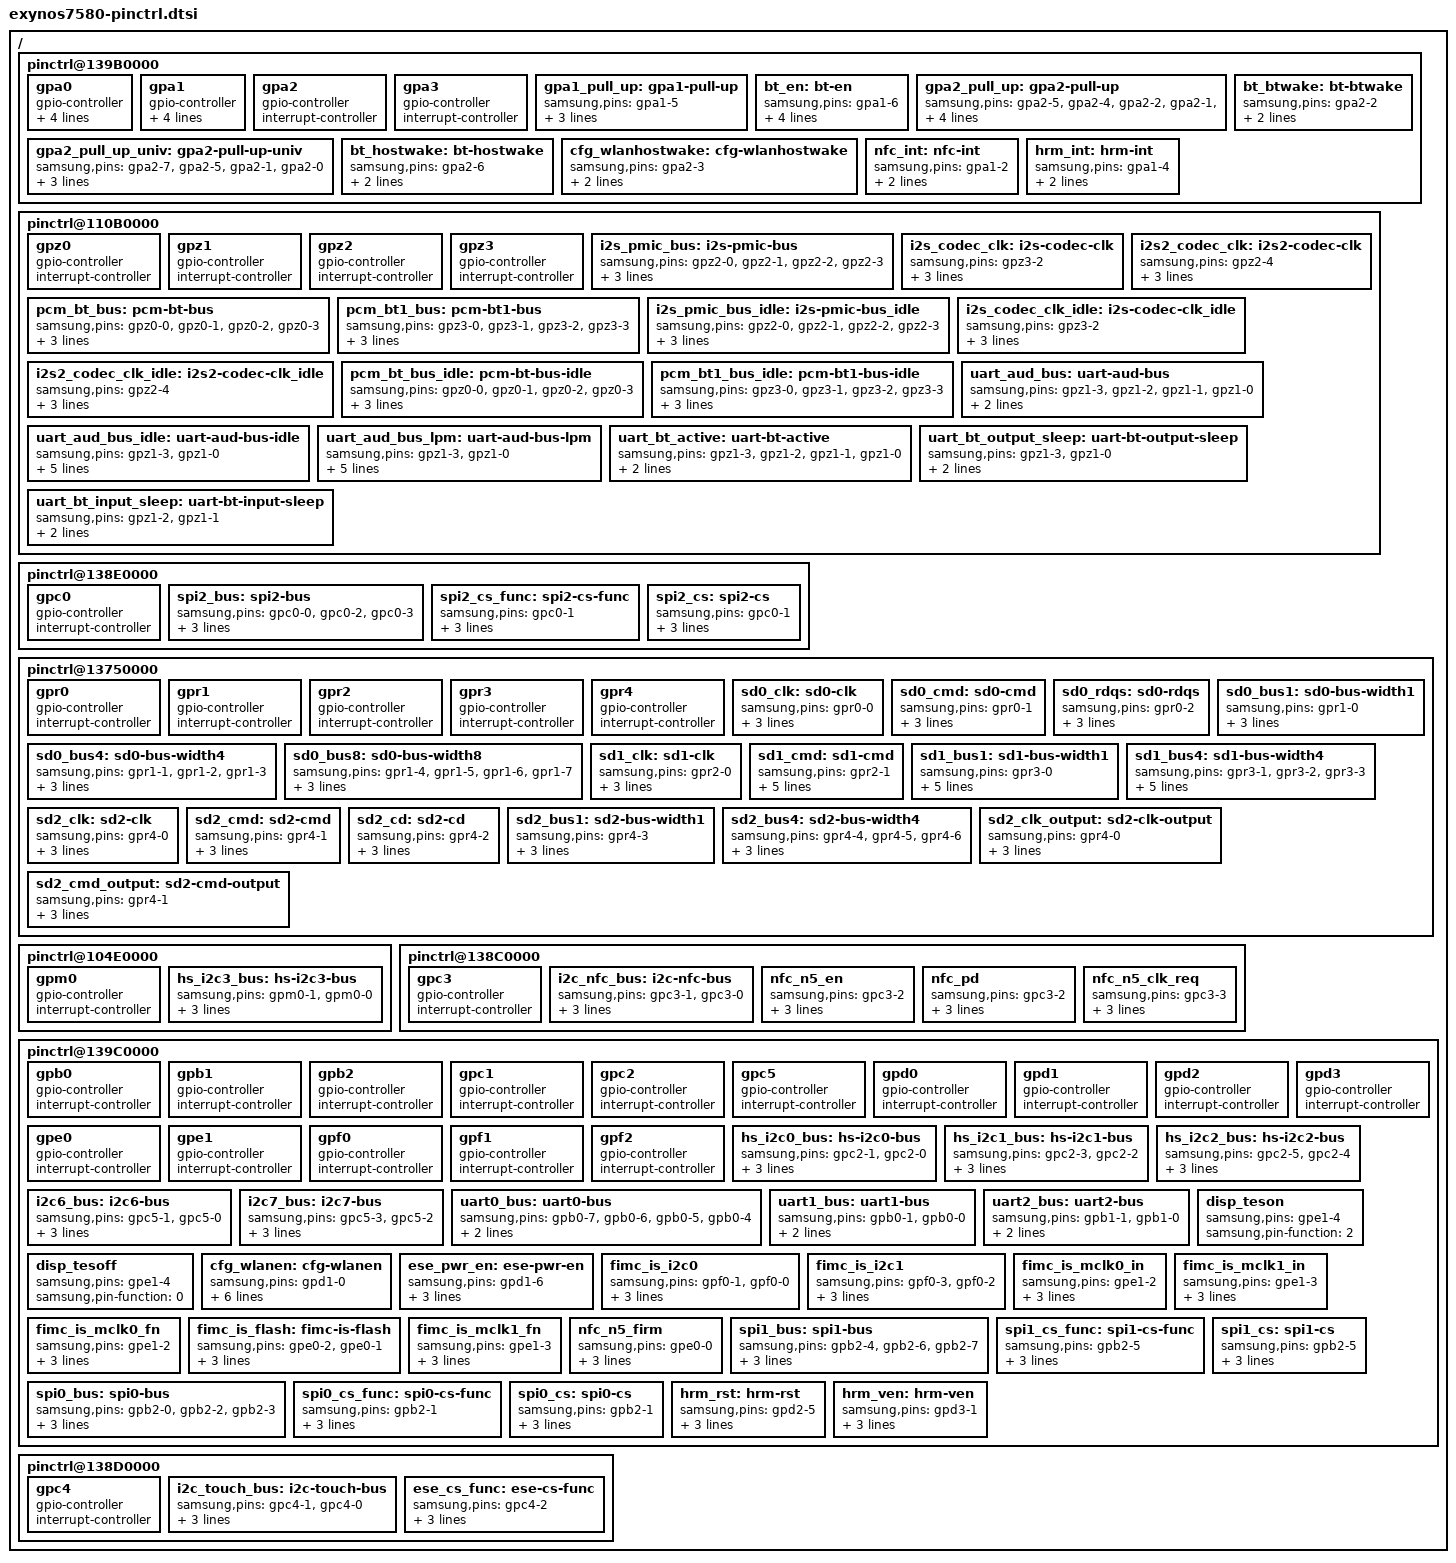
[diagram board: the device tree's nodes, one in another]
/*
 * Samsung's Exynos7580 SoC pin-mux and pin-config device tree source
 *
 * Copyright (c) 2014 Samsung Electronics Co., Ltd.
 *		http://www.samsung.com
 *
 * Samsung's Exynos7580 SoC pin-mux and pin-config options are listed as device
 * tree nodes are listed in this file.
 *
 * This program is free software; you can redistribute it and/or modify
 * it under the terms of the GNU General Public License version 2 as
 * published by the Free Software Foundation.
*/

/ {
	pinctrl@139B0000 {
		gpa0: gpa0 {
			gpio-controller;
			#gpio-cells = <2>;

			interrupt-controller;
			#interrupt-cells = <3>;
			interrupt-parent = <&gic>;
			interrupts = <0 0 0>, <0 1 0>, <0 2 0>, <0 3 0>,
				     <0 4 0>, <0 5 0>, <0 6 0>, <0 7 0>;
		};

		gpa1: gpa1 {
			gpio-controller;
			#gpio-cells = <2>;

			interrupt-controller;
			#interrupt-cells = <3>;
			interrupt-parent = <&gic>;
			interrupts = <0 8 0>, <0 9 0>, <0 10 0>, <0 11 0>,
				     <0 12 0>, <0 13 0>, <0 14 0>, <0 15 0>;
		};

		gpa2: gpa2 {
			gpio-controller;
			#gpio-cells = <2>;

			interrupt-controller;
			#interrupt-cells = <2>;
		};

		gpa3: gpa3 {
			gpio-controller;
			#gpio-cells = <2>;

			interrupt-controller;
			#interrupt-cells = <2>;
		};

		gpa1_pull_up: gpa1-pull-up {
			samsung,pins = "gpa1-5";
			samsung,pin-function = <0xf>;
			samsung,pin-pud = <3>;
			samsung,pin-drv = <0>;
		};

		bt_en: bt-en {
			samsung,pins ="gpa1-6";
			samsung,pin-function = <1>;
			samsung,pin-pud = <0>;
			samsung,pin-con-pdn = <3>;
			samsung,pin-pud-pdn = <0>;
		};

		gpa2_pull_up: gpa2-pull-up {
			samsung,pins = "gpa2-5", "gpa2-4", "gpa2-2", "gpa2-1", "gpa2-0";
			samsung,pin-function = <0xf>;
			samsung,pin-pud = <3>;
			samsung,pin-drv = <0>;
		};

		gpa2_pull_up_univ: gpa2-pull-up-univ {
			samsung,pins = "gpa2-7", "gpa2-5", "gpa2-1", "gpa2-0";
			samsung,pin-function = <0xf>;
			samsung,pin-pud = <3>;
			samsung,pin-drv = <0>;
		};

		bt_btwake: bt-btwake {
			samsung,pins = "gpa2-2";
			samsung,pin-function = <1>;
			samsung,pin-pud = <0>;
		};

		bt_hostwake: bt-hostwake {
			samsung,pins = "gpa2-6";
			samsung,pin-function = <0>;
			samsung,pin-pud = <0>;
		};
		
		cfg_wlanhostwake: cfg-wlanhostwake {
                	samsung,pins = "gpa2-3";
                	samsung,pin-function = <0>;
                	samsung,pin-pud = <1>;
                };

		nfc_int: nfc-int {
			samsung,pins = "gpa1-2";
			samsung,pin-function = <0>;
			samsung,pin-pud = <1>;
		};

		hrm_int: hrm-int {
			samsung,pins = "gpa1-4";
			samsung,pin-function = <0xf>;
			samsung,pin-pud = <1>;
		};
	};

	pinctrl@110B0000 {
		gpz0: gpz0 {
			gpio-controller;
			#gpio-cells = <2>;

			interrupt-controller;
			#interrupt-cells = <2>;
		};

		gpz1: gpz1 {
			gpio-controller;
			#gpio-cells = <2>;

			interrupt-controller;
			#interrupt-cells = <2>;
		};

		gpz2: gpz2 {
			gpio-controller;
			#gpio-cells = <2>;

			interrupt-controller;
			#interrupt-cells = <2>;
		};

		gpz3: gpz3 {
			gpio-controller;
			#gpio-cells = <2>;

			interrupt-controller;
			#interrupt-cells = <2>;
		};

		i2s_pmic_bus: i2s-pmic-bus {
			samsung,pins = "gpz2-0", "gpz2-1", "gpz2-2", "gpz2-3";
			samsung,pin-function = <2>;
			samsung,pin-pud = <1>;
			samsung,pin-drv = <0>;
		};

		i2s_codec_clk: i2s-codec-clk {
			samsung,pins = "gpz3-2";
			samsung,pin-function = <4>;
			samsung,pin-pud = <1>;
			samsung,pin-drv = <0>;
		};

		/* XTSCPU_TOUT pin configuration as codec MCLK */
		i2s2_codec_clk: i2s2-codec-clk {
			samsung,pins = "gpz2-4";
			samsung,pin-function = <2>;
			samsung,pin-pud = <1>;
			samsung,pin-drv = <0>;
		};

		pcm_bt_bus: pcm-bt-bus {
			samsung,pins = "gpz0-0", "gpz0-1", "gpz0-2", "gpz0-3";
			samsung,pin-function = <2>;
			samsung,pin-pud = <1>;
			samsung,pin-drv = <0>;
		};

		pcm_bt1_bus: pcm-bt1-bus {
			samsung,pins = "gpz3-0", "gpz3-1", "gpz3-2", "gpz3-3";
			samsung,pin-function = <2>;
			samsung,pin-pud = <1>;
			samsung,pin-drv = <0>;
		};

		i2s_pmic_bus_idle: i2s-pmic-bus_idle {
			samsung,pins = "gpz2-0", "gpz2-1", "gpz2-2", "gpz2-3";
			samsung,pin-function = <0>;
			samsung,pin-pud = <1>;
			samsung,pin-drv = <0>;
		};

		i2s_codec_clk_idle: i2s-codec-clk_idle {
			samsung,pins = "gpz3-2";
			samsung,pin-function = <0>;
			samsung,pin-pud = <1>;
			samsung,pin-drv = <0>;
		};

		i2s2_codec_clk_idle: i2s2-codec-clk_idle {
			samsung,pins = "gpz2-4";
			samsung,pin-function = <0>;
			samsung,pin-pud = <1>;
			samsung,pin-drv = <0>;
		};

		pcm_bt_bus_idle: pcm-bt-bus-idle {
			samsung,pins = "gpz0-0", "gpz0-1", "gpz0-2", "gpz0-3";
			samsung,pin-function = <0>;
			samsung,pin-pud = <1>;
			samsung,pin-drv = <0>;
		};

		pcm_bt1_bus_idle: pcm-bt1-bus-idle {
			samsung,pins = "gpz3-0", "gpz3-1", "gpz3-2", "gpz3-3";
			samsung,pin-function = <0>;
			samsung,pin-pud = <1>;
			samsung,pin-drv = <0>;
		};

		uart_aud_bus: uart-aud-bus {
			samsung,pins = "gpz1-3", "gpz1-2", "gpz1-1", "gpz1-0";
			samsung,pin-function = <2>;
			samsung,pin-pud = <0>;
		};

		uart_aud_bus_idle: uart-aud-bus-idle {
			samsung,pins = "gpz1-3", "gpz1-0";
			samsung,pin-function = <1>;
			samsung,pin-val = <1>;
			samsung,pin-pud = <0>;
			samsung,pin-con-pdn = <1>;
			samsung,pin-pud-pdn = <3>;
		};

		uart_aud_bus_lpm: uart-aud-bus-lpm {
			samsung,pins = "gpz1-3", "gpz1-0";
			samsung,pin-function = <1>;
			samsung,pin-val = <1>;
			samsung,pin-pud = <0>;
			samsung,pin-con-pdn = <1>;
			samsung,pin-pud-pdn = <3>;
		};

		uart_bt_active: uart-bt-active {
			samsung,pins = "gpz1-3", "gpz1-2", "gpz1-1", "gpz1-0";
			samsung,pin-function = <2>;
			samsung,pin-pud = <3>;
		};

		uart_bt_output_sleep: uart-bt-output-sleep {
			samsung,pins = "gpz1-3", "gpz1-0";
			samsung,pin-con-pdn = <1>;
			samsung,pin-pud-pdn = <3>;
		};

		uart_bt_input_sleep: uart-bt-input-sleep {
			samsung,pins = "gpz1-2", "gpz1-1";
			samsung,pin-con-pdn = <2>;
			samsung,pin-pud-pdn = <3>;
		};
	};

	pinctrl@138E0000 {
		gpc0: gpc0 {
			gpio-controller;
			#gpio-cells = <2>;

			interrupt-controller;
			#interrupt-cells = <2>;
		};

		spi2_bus: spi2-bus {
			samsung,pins = "gpc0-0", "gpc0-2", "gpc0-3";
			samsung,pin-function = <2>;
			samsung,pin-pud = <3>;
			samsung,pin-drv = <0>;
		};

		spi2_cs_func: spi2-cs-func {
			samsung,pins = "gpc0-1";
			samsung,pin-function = <2>;
			samsung,pin-pud = <3>;
			samsung,pin-drv = <0>;
		};

		spi2_cs: spi2-cs {
			samsung,pins = "gpc0-1";
			samsung,pin-function = <1>;
			samsung,pin-pud = <3>;
			samsung,pin-drv = <0>;
		};
	};

	pinctrl@13750000 {
		gpr0: gpr0 {
			gpio-controller;
			#gpio-cells = <2>;

			interrupt-controller;
			#interrupt-cells = <2>;
		};

		gpr1: gpr1 {
			gpio-controller;
			#gpio-cells = <2>;

			interrupt-controller;
			#interrupt-cells = <2>;
		};

		gpr2: gpr2 {
			gpio-controller;
			#gpio-cells = <2>;

			interrupt-controller;
			#interrupt-cells = <2>;
		};

		gpr3: gpr3 {
			gpio-controller;
			#gpio-cells = <2>;

			interrupt-controller;
			#interrupt-cells = <2>;
		};

		gpr4: gpr4 {
			gpio-controller;
			#gpio-cells = <2>;

			interrupt-controller;
			#interrupt-cells = <2>;
		};

		sd0_clk: sd0-clk {
			samsung,pins = "gpr0-0";
			samsung,pin-function = <2>;
			samsung,pin-pud = <0>;
			samsung,pin-drv = <2>;
		};

		sd0_cmd: sd0-cmd {
			samsung,pins = "gpr0-1";
			samsung,pin-function = <2>;
			samsung,pin-pud = <3>;
			samsung,pin-drv = <2>;
		};

		sd0_rdqs: sd0-rdqs {
			samsung,pins = "gpr0-2";
			samsung,pin-function = <2>;
			samsung,pin-pud = <1>;
			samsung,pin-drv = <2>;
		};

		sd0_bus1: sd0-bus-width1 {
			samsung,pins = "gpr1-0";
			samsung,pin-function = <2>;
			samsung,pin-pud = <3>;
			samsung,pin-drv = <2>;
		};

		sd0_bus4: sd0-bus-width4 {
			samsung,pins = "gpr1-1", "gpr1-2", "gpr1-3";
			samsung,pin-function = <2>;
			samsung,pin-pud = <3>;
			samsung,pin-drv = <2>;
		};

		sd0_bus8: sd0-bus-width8 {
			samsung,pins = "gpr1-4", "gpr1-5", "gpr1-6", "gpr1-7";
			samsung,pin-function = <2>;
			samsung,pin-pud = <3>;
			samsung,pin-drv = <2>;
		};

		sd1_clk: sd1-clk {
			samsung,pins = "gpr2-0";
			samsung,pin-function = <2>;
			samsung,pin-pud = <0>;
			samsung,pin-drv = <3>;
		};

		sd1_cmd: sd1-cmd {
			samsung,pins = "gpr2-1";
			samsung,pin-function = <2>;
			samsung,pin-pud = <3>;
			samsung,pin-drv = <3>;
			samsung,pin-con-pdn = <2>;
			samsung,pin-pud-pdn = <3>;
		};

		sd1_bus1: sd1-bus-width1 {
			samsung,pins = "gpr3-0";
			samsung,pin-function = <2>;
			samsung,pin-pud = <3>;
			samsung,pin-drv = <3>;
			samsung,pin-con-pdn = <2>;
			samsung,pin-pud-pdn = <3>;
		};

		sd1_bus4: sd1-bus-width4 {
			samsung,pins = "gpr3-1", "gpr3-2", "gpr3-3";
			samsung,pin-function = <2>;
			samsung,pin-pud = <3>;
			samsung,pin-drv = <3>;
			samsung,pin-con-pdn = <2>;
			samsung,pin-pud-pdn = <3>;
		};

		sd2_clk: sd2-clk {
			samsung,pins = "gpr4-0";
			samsung,pin-function = <2>;
			samsung,pin-pud = <0>;
			samsung,pin-drv = <2>;
		};

		sd2_cmd: sd2-cmd {
			samsung,pins = "gpr4-1";
			samsung,pin-function = <2>;
			samsung,pin-pud = <0>;
			samsung,pin-drv = <2>;
		};

		sd2_cd: sd2-cd {
			samsung,pins = "gpr4-2";
			samsung,pin-function = <2>;
			samsung,pin-pud = <0>;
			samsung,pin-drv = <2>;
		};

		sd2_bus1: sd2-bus-width1 {
			samsung,pins = "gpr4-3";
			samsung,pin-function = <2>;
			samsung,pin-pud = <0>;
			samsung,pin-drv = <2>;
		};

		sd2_bus4: sd2-bus-width4 {
			samsung,pins = "gpr4-4", "gpr4-5", "gpr4-6";
			samsung,pin-function = <2>;
			samsung,pin-pud = <0>;
			samsung,pin-drv = <2>;
		};

		sd2_clk_output: sd2-clk-output {
			samsung,pins = "gpr4-0";
			samsung,pin-function = <1>;
			samsung,pin-pud = <0>;
			samsung,pin-drv = <2>;
		};

		sd2_cmd_output: sd2-cmd-output {
			samsung,pins = "gpr4-1";
			samsung,pin-function = <1>;
			samsung,pin-pud = <0>;
			samsung,pin-drv = <2>;
		};

	};

	pinctrl@104E0000 {
		gpm0: gpm0 {
			gpio-controller;
			#gpio-cells = <2>;

			interrupt-controller;
			#interrupt-cells = <2>;
		};

		hs_i2c3_bus: hs-i2c3-bus {
			samsung,pins = "gpm0-1", "gpm0-0";
			samsung,pin-function = <2>;
			samsung,pin-pud = <3>;
			samsung,pin-drv = <2>;
		};
	};

	pinctrl@138C0000 {
		gpc3: gpc3 {
			gpio-controller;
			#gpio-cells = <2>;

			interrupt-controller;
			#interrupt-cells = <2>;
		};

		i2c_nfc_bus: i2c-nfc-bus {
			samsung,pins = "gpc3-1", "gpc3-0";
			samsung,pin-function = <2>;
			samsung,pin-pud = <3>;
			samsung,pin-drv = <0>;
		};

		nfc_n5_en: nfc_n5_en {
			samsung,pins = "gpc3-2";
			samsung,pin-function = <1>;
			samsung,pin-pud = <1>;
			samsung,pin-val = <1>;
		};

		nfc_pd: nfc_pd {
			samsung,pins = "gpc3-2";
			samsung,pin-function = <2>;
			samsung,pin-pud = <1>;
			samsung,pin-drv = <0>;
		};

		nfc_n5_clk_req: nfc_n5_clk_req {
			samsung,pins = "gpc3-3";
			samsung,pin-function = <2>;
			samsung,pin-pud = <1>;
			samsung,pin-drv = <0>;
		};
	};

	pinctrl@139C0000 {
		gpb0: gpb0 {
			gpio-controller;
			#gpio-cells = <2>;

			interrupt-controller;
			#interrupt-cells = <2>;
		};

		gpb1: gpb1 {
			gpio-controller;
			#gpio-cells = <2>;

			interrupt-controller;
			#interrupt-cells = <2>;
		};

		gpb2: gpb2 {
			gpio-controller;
			#gpio-cells = <2>;

			interrupt-controller;
			#interrupt-cells = <2>;
		};

		gpc1: gpc1 {
			gpio-controller;
			#gpio-cells = <2>;

			interrupt-controller;
			#interrupt-cells = <2>;
		};

		gpc2: gpc2 {
			gpio-controller;
			#gpio-cells = <2>;

			interrupt-controller;
			#interrupt-cells = <2>;
		};

		gpc5: gpc5 {
			gpio-controller;
			#gpio-cells = <2>;

			interrupt-controller;
			#interrupt-cells = <2>;
		};

		gpd0: gpd0 {
			gpio-controller;
			#gpio-cells = <2>;

			interrupt-controller;
			#interrupt-cells = <2>;
		};

		gpd1: gpd1 {
			gpio-controller;
			#gpio-cells = <2>;

			interrupt-controller;
			#interrupt-cells = <2>;
		};

		gpd2: gpd2 {
			gpio-controller;
			#gpio-cells = <2>;

			interrupt-controller;
			#interrupt-cells = <2>;
		};

		gpd3: gpd3 {
			gpio-controller;
			#gpio-cells = <2>;

			interrupt-controller;
			#interrupt-cells = <2>;
		};

		gpe0: gpe0 {
			gpio-controller;
			#gpio-cells = <2>;

			interrupt-controller;
			#interrupt-cells = <2>;
		};

		gpe1: gpe1 {
			gpio-controller;
			#gpio-cells = <2>;

			interrupt-controller;
			#interrupt-cells = <2>;
		};

		gpf0: gpf0 {
			gpio-controller;
			#gpio-cells = <2>;

			interrupt-controller;
			#interrupt-cells = <2>;
		};

		gpf1: gpf1 {
			gpio-controller;
			#gpio-cells = <2>;

			interrupt-controller;
			#interrupt-cells = <2>;
		};

		gpf2: gpf2 {
			gpio-controller;
			#gpio-cells = <2>;

			interrupt-controller;
			#interrupt-cells = <2>;
		};

		hs_i2c0_bus: hs-i2c0-bus {
			samsung,pins = "gpc2-1", "gpc2-0";
			samsung,pin-function = <2>;
			samsung,pin-pud = <3>;
			samsung,pin-drv = <0>;
		};

		hs_i2c1_bus: hs-i2c1-bus {
			samsung,pins = "gpc2-3", "gpc2-2";
			samsung,pin-function = <2>;
			samsung,pin-pud = <3>;
			samsung,pin-drv = <0>;
		};

		hs_i2c2_bus: hs-i2c2-bus {
			samsung,pins = "gpc2-5", "gpc2-4";
			samsung,pin-function = <2>;
			samsung,pin-pud = <0>;
			samsung,pin-drv = <0>;
		};

		i2c6_bus: i2c6-bus {
			samsung,pins = "gpc5-1", "gpc5-0";
			samsung,pin-function = <2>;
			samsung,pin-pud = <3>;
			samsung,pin-drv = <0>;
		};

		i2c7_bus: i2c7-bus {
			samsung,pins = "gpc5-3", "gpc5-2";
			samsung,pin-function = <2>;
			samsung,pin-pud = <3>;
			samsung,pin-drv = <0>;
		};

		uart0_bus: uart0-bus {
			samsung,pins = "gpb0-7", "gpb0-6", "gpb0-5", "gpb0-4";
			samsung,pin-function = <2>;
			samsung,pin-pud = <0>;
		};

		uart1_bus: uart1-bus {
			samsung,pins = "gpb0-1", "gpb0-0";
			samsung,pin-function = <2>;
			samsung,pin-pud = <0>;
		};

		uart2_bus: uart2-bus {
			samsung,pins = "gpb1-1", "gpb1-0";
			samsung,pin-function = <2>;
			samsung,pin-pud = <0>;
		};

		disp_teson: disp_teson {
			samsung,pins = "gpe1-4";
			samsung,pin-function = <2>;
		};

		disp_tesoff: disp_tesoff {
			samsung,pins = "gpe1-4";
			samsung,pin-function = <0>;
		};
		
		cfg_wlanen: cfg-wlanen  {       /* WLAN_EN on carmen2 */
                	samsung,pins = "gpd1-0";
                	samsung,pin-function = <1>;
                	samsung,pin-pud = <0>;
                	samsung,pin-drv = <3>;
                	samsung,pin-con-pdn = <3>;
                	samsung,pin-pud-pdn = <0>;
			samsung,pin-val = <0>;
                };

		ese_pwr_en: ese-pwr-en {
			samsung,pins = "gpd1-6";
			samsung,pin-function = <1>;
			samsung,pin-pud = <1>;
			samsung,pin-drv = <3>;
		};

		fimc_is_i2c0: fimc_is_i2c0 {
			samsung,pins = "gpf0-1", "gpf0-0";
			samsung,pin-function = <2>;
			samsung,pin-pud = <0>;
			samsung,pin-drv = <0>;
		};

		fimc_is_i2c1: fimc_is_i2c1 {
			samsung,pins = "gpf0-3", "gpf0-2";
			samsung,pin-function = <2>;
			samsung,pin-pud = <0>;
			samsung,pin-drv = <0>;
		};

		fimc_is_mclk0_in: fimc_is_mclk0_in {
			samsung,pins = "gpe1-2";
			samsung,pin-function = <0>;
			samsung,pin-pud = <0>;
			samsung,pin-drv = <0>;
		};

		fimc_is_mclk1_in: fimc_is_mclk1_in {
			samsung,pins = "gpe1-3";
			samsung,pin-function = <0>;
			samsung,pin-pud = <0>;
			samsung,pin-drv = <0>;
		};

		fimc_is_mclk0_fn: fimc_is_mclk0_fn {
			samsung,pins = "gpe1-2";
			samsung,pin-function = <2>;
			samsung,pin-pud = <0>;
			samsung,pin-drv = <0>;
		};

		fimc_is_flash: fimc-is-flash {
			samsung,pins = "gpe0-2", "gpe0-1";
			samsung,pin-function = <2>;
			samsung,pin-pud = <0>;
			samsung,pin-drv = <0>;
		};

		fimc_is_mclk1_fn: fimc_is_mclk1_fn {
			samsung,pins = "gpe1-3";
			samsung,pin-function = <2>;
			samsung,pin-pud = <0>;
			samsung,pin-drv = <0>;
		};

		nfc_n5_firm: nfc_n5_firm {
			samsung,pins = "gpe0-0";
			samsung,pin-function = <1>;
			samsung,pin-pud = <1>;
			samsung,pin-val = <1>;
		};

		spi1_bus: spi1-bus {
			samsung,pins = "gpb2-4", "gpb2-6", "gpb2-7";
			samsung,pin-function = <2>;
			samsung,pin-pud = <3>;
			samsung,pin-drv = <0>;
		};

		spi1_cs_func: spi1-cs-func {
			samsung,pins = "gpb2-5";
			samsung,pin-function = <2>;
			samsung,pin-pud = <3>;
			samsung,pin-drv = <0>;
		};

		spi1_cs: spi1-cs {
			samsung,pins = "gpb2-5";
			samsung,pin-function = <1>;
			samsung,pin-pud = <3>;
			samsung,pin-drv = <0>;
		};

		spi0_bus: spi0-bus {
			samsung,pins = "gpb2-0", "gpb2-2", "gpb2-3";
			samsung,pin-function = <2>;
			samsung,pin-pud = <3>;
			samsung,pin-drv = <0>;
		};

		spi0_cs_func: spi0-cs-func {
			samsung,pins = "gpb2-1";
			samsung,pin-function = <2>;
			samsung,pin-pud = <3>;
			samsung,pin-drv = <0>;
		};

		spi0_cs: spi0-cs {
			samsung,pins = "gpb2-1";
			samsung,pin-function = <1>;
			samsung,pin-pud = <3>;
			samsung,pin-drv = <0>;
		};

		hrm_rst: hrm-rst {
			samsung,pins = "gpd2-5";
			samsung,pin-function = <1>;
			samsung,pin-pud = <1>;
			samsung,pin-val = <0>;
		};

		hrm_ven: hrm-ven {
			samsung,pins = "gpd3-1";
			samsung,pin-function = <1>;
			samsung,pin-pud = <1>;
			samsung,pin-val = <0>;
		};
	};

	pinctrl@138D0000 {
		gpc4: gpc4 {
			gpio-controller;
			#gpio-cells = <2>;

			interrupt-controller;
			#interrupt-cells = <2>;
		};

		i2c_touch_bus: i2c-touch-bus {
			samsung,pins = "gpc4-1", "gpc4-0";
			samsung,pin-function = <2>;
			samsung,pin-pud = <0>;
			samsung,pin-drv = <0>;
		};

		ese_cs_func: ese-cs-func {
			samsung,pins ="gpc4-2";
			samsung,pin-function = <1>;
			samsung,pin-pud = <3>;
			samsung,pin-drv = <0>;

		};
	};
};
